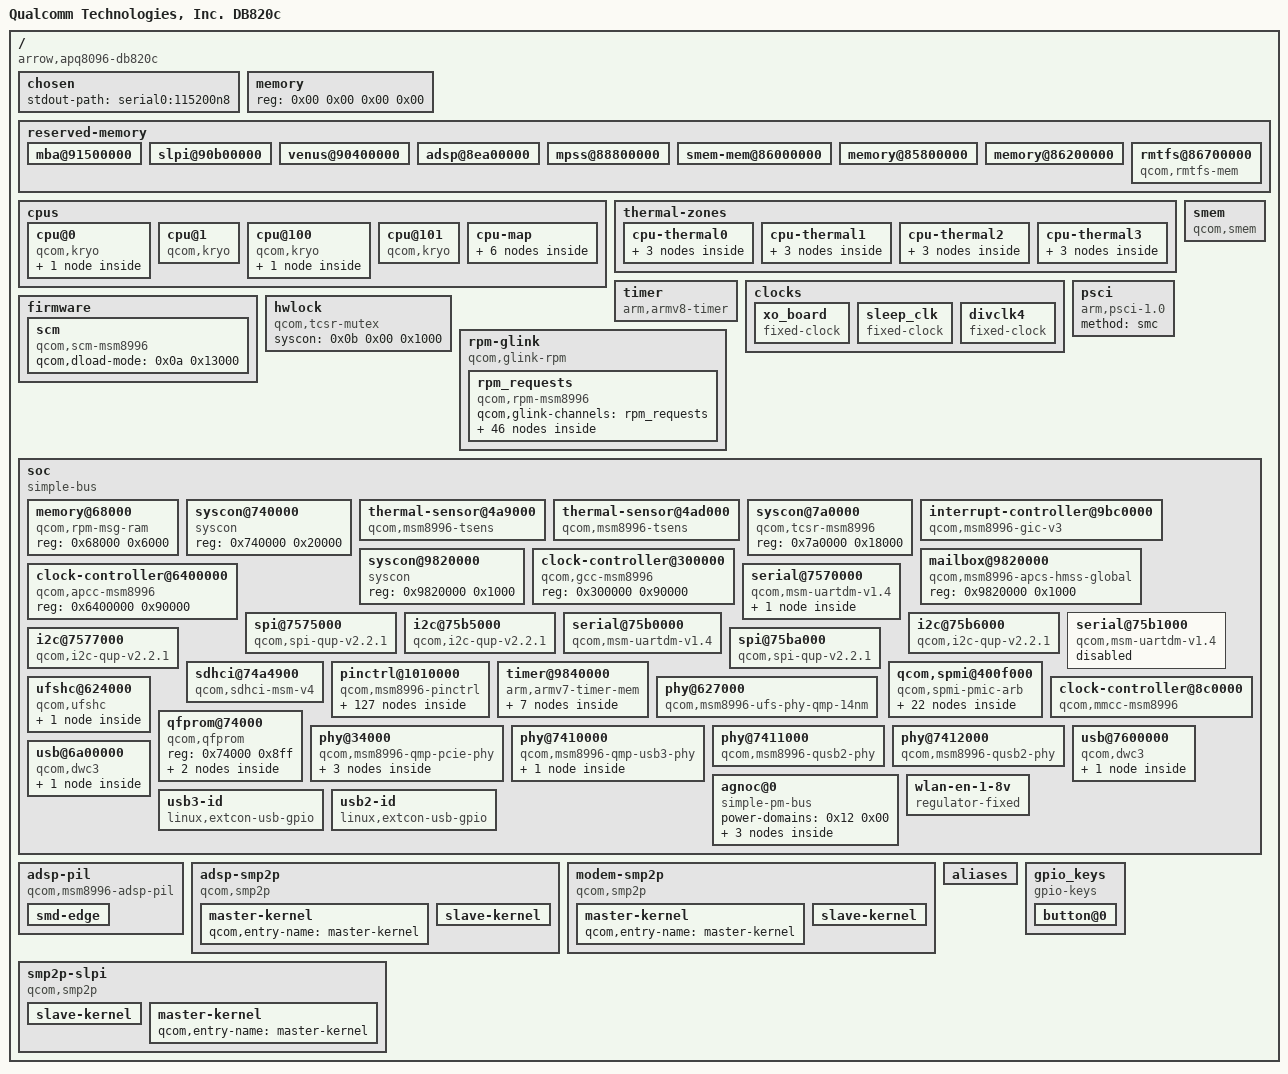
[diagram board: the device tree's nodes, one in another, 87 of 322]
/dts-v1/;

/ {
	model = "Qualcomm Technologies, Inc. DB820c";
	interrupt-parent = <0x01>;
	#address-cells = <0x02>;
	#size-cells = <0x02>;
	compatible = "arrow,apq8096-db820c\0qcom,apq8096-sbc";

	chosen {
		stdout-path = "serial0:115200n8";
	};

	memory {
		device_type = "memory";
		reg = <0x00 0x00 0x00 0x00>;
	};

	reserved-memory {
		#address-cells = <0x02>;
		#size-cells = <0x02>;
		ranges;

		mba@91500000 {
			reg = <0x00 0x91500000 0x00 0x200000>;
			no-map;
		};

		slpi@90b00000 {
			reg = <0x00 0x90b00000 0x00 0xa00000>;
			no-map;
		};

		venus@90400000 {
			reg = <0x00 0x90400000 0x00 0x700000>;
			no-map;
		};

		adsp@8ea00000 {
			reg = <0x00 0x8ea00000 0x00 0x1a00000>;
			no-map;
			phandle = <0x5b>;
		};

		mpss@88800000 {
			reg = <0x00 0x88800000 0x00 0x6200000>;
			no-map;
		};

		smem-mem@86000000 {
			reg = <0x00 0x86000000 0x00 0x200000>;
			no-map;
			phandle = <0x0c>;
		};

		memory@85800000 {
			reg = <0x00 0x85800000 0x00 0x800000>;
			no-map;
		};

		memory@86200000 {
			reg = <0x00 0x86200000 0x00 0x2600000>;
			no-map;
		};

		rmtfs@86700000 {
			compatible = "qcom,rmtfs-mem";
			size = <0x00 0x200000>;
			alloc-ranges = <0x00 0xa0000000 0x00 0x2000000>;
			no-map;
			qcom,client-id = <0x01>;
			qcom,vmid = <0x0f>;
		};
	};

	cpus {
		#address-cells = <0x02>;
		#size-cells = <0x00>;

		cpu@0 {
			device_type = "cpu";
			compatible = "qcom,kryo";
			reg = <0x00 0x00>;
			enable-method = "psci";
			next-level-cache = <0x02>;
			phandle = <0x04>;

			l2-cache {
				compatible = "cache";
				cache-level = <0x02>;
				phandle = <0x02>;
			};
		};

		cpu@1 {
			device_type = "cpu";
			compatible = "qcom,kryo";
			reg = <0x00 0x01>;
			enable-method = "psci";
			next-level-cache = <0x02>;
			phandle = <0x05>;
		};

		cpu@100 {
			device_type = "cpu";
			compatible = "qcom,kryo";
			reg = <0x00 0x100>;
			enable-method = "psci";
			next-level-cache = <0x03>;
			phandle = <0x06>;

			l2-cache {
				compatible = "cache";
				cache-level = <0x02>;
				phandle = <0x03>;
			};
		};

		cpu@101 {
			device_type = "cpu";
			compatible = "qcom,kryo";
			reg = <0x00 0x101>;
			enable-method = "psci";
			next-level-cache = <0x03>;
			phandle = <0x07>;
		};

		cpu-map {

			cluster0 {

				core0 {
					cpu = <0x04>;
				};

				core1 {
					cpu = <0x05>;
				};
			};

			cluster1 {

				core0 {
					cpu = <0x06>;
				};

				core1 {
					cpu = <0x07>;
				};
			};
		};
	};

	thermal-zones {

		cpu-thermal0 {
			polling-delay-passive = <0xfa>;
			polling-delay = <0x3e8>;
			thermal-sensors = <0x08 0x03>;

			trips {

				trip0 {
					temperature = <0x124f8>;
					hysteresis = <0x7d0>;
					type = "passive";
				};

				trip1 {
					temperature = <0x1adb0>;
					hysteresis = <0x7d0>;
					type = "critical";
				};
			};
		};

		cpu-thermal1 {
			polling-delay-passive = <0xfa>;
			polling-delay = <0x3e8>;
			thermal-sensors = <0x08 0x05>;

			trips {

				trip0 {
					temperature = <0x124f8>;
					hysteresis = <0x7d0>;
					type = "passive";
				};

				trip1 {
					temperature = <0x1adb0>;
					hysteresis = <0x7d0>;
					type = "critical";
				};
			};
		};

		cpu-thermal2 {
			polling-delay-passive = <0xfa>;
			polling-delay = <0x3e8>;
			thermal-sensors = <0x08 0x08>;

			trips {

				trip0 {
					temperature = <0x124f8>;
					hysteresis = <0x7d0>;
					type = "passive";
				};

				trip1 {
					temperature = <0x1adb0>;
					hysteresis = <0x7d0>;
					type = "critical";
				};
			};
		};

		cpu-thermal3 {
			polling-delay-passive = <0xfa>;
			polling-delay = <0x3e8>;
			thermal-sensors = <0x08 0x0a>;

			trips {

				trip0 {
					temperature = <0x124f8>;
					hysteresis = <0x7d0>;
					type = "passive";
				};

				trip1 {
					temperature = <0x1adb0>;
					hysteresis = <0x7d0>;
					type = "critical";
				};
			};
		};
	};

	timer {
		compatible = "arm,armv8-timer";
		interrupts = <0x01 0x0d 0x08 0x01 0x0e 0x08 0x01 0x0b 0x08 0x01 0x0a 0x08>;
	};

	clocks {

		xo_board {
			compatible = "fixed-clock";
			#clock-cells = <0x00>;
			clock-frequency = <0x124f800>;
			clock-output-names = "xo_board";
			phandle = <0x25>;
		};

		sleep_clk {
			compatible = "fixed-clock";
			#clock-cells = <0x00>;
			clock-frequency = <0x7ffc>;
			clock-output-names = "sleep_clk";
		};

		divclk4 {
			compatible = "fixed-clock";
			#clock-cells = <0x00>;
			clock-frequency = <0x8000>;
			clock-output-names = "divclk4";
			pinctrl-names = "default";
			pinctrl-0 = <0x09>;
			phandle = <0x16>;
		};
	};

	psci {
		compatible = "arm,psci-1.0";
		method = "smc";
	};

	firmware {

		scm {
			compatible = "qcom,scm-msm8996";
			qcom,dload-mode = <0x0a 0x13000>;
		};
	};

	hwlock {
		compatible = "qcom,tcsr-mutex";
		syscon = <0x0b 0x00 0x1000>;
		#hwlock-cells = <0x01>;
		phandle = <0x0d>;
	};

	smem {
		compatible = "qcom,smem";
		memory-region = <0x0c>;
		hwlocks = <0x0d 0x03>;
	};

	rpm-glink {
		compatible = "qcom,glink-rpm";
		interrupts = <0x00 0xa8 0x01>;
		qcom,rpm-msg-ram = <0x0e>;
		mboxes = <0x0f 0x00>;

		rpm_requests {
			compatible = "qcom,rpm-msm8996";
			qcom,glink-channels = "rpm_requests";

			qcom,rpmcc {
				compatible = "qcom,rpmcc-msm8996";
				#clock-cells = <0x01>;
				phandle = <0x36>;
			};

			pm8994-regulators {
				compatible = "qcom,rpm-pm8994-regulators";
				vdd_l1-supply = <0x10>;
				vdd_l2_l26_l28-supply = <0x10>;
				vdd_l3_l11-supply = <0x10>;
				vdd_l4_l27_l31-supply = <0x10>;
				vdd_l5_l7-supply = <0x11>;
				vdd_l14_l15-supply = <0x11>;
				vdd_l20_l21-supply = <0x11>;
				vdd_l25-supply = <0x10>;

				s1 {
				};

				s2 {
				};

				s3 {
					regulator-min-microvolt = <0x13d620>;
					regulator-max-microvolt = <0x13d620>;
					phandle = <0x10>;
				};

				s4 {
					regulator-min-microvolt = <0x1b7740>;
					regulator-max-microvolt = <0x1b7740>;
					regulator-always-on;
					phandle = <0x39>;
				};

				s5 {
					regulator-min-microvolt = <0x20ce70>;
					regulator-max-microvolt = <0x20ce70>;
					phandle = <0x11>;
				};

				s6 {
				};

				s7 {
					regulator-min-microvolt = "\0\f5";
					regulator-max-microvolt = "\0\f5";
				};

				s8 {
				};

				s9 {
				};

				s10 {
				};

				s11 {
				};

				s12 {
				};

				l1 {
					regulator-min-microvolt = <0xf4240>;
					regulator-max-microvolt = <0xf4240>;
				};

				l2 {
					regulator-min-microvolt = <0x1312d0>;
					regulator-max-microvolt = <0x1312d0>;
				};

				l3 {
					regulator-min-microvolt = <0xcf850>;
					regulator-max-microvolt = <0xcf850>;
				};

				l4 {
					regulator-min-microvolt = <0x12b128>;
					regulator-max-microvolt = <0x12b128>;
				};

				l5 {
				};

				l6 {
					regulator-min-microvolt = <0x124f80>;
					regulator-max-microvolt = <0x124f80>;
				};

				l7 {
				};

				l8 {
					regulator-min-microvolt = <0x1b7740>;
					regulator-max-microvolt = <0x1b7740>;
				};

				l9 {
					regulator-min-microvolt = <0x1b7740>;
					regulator-max-microvolt = <0x1b7740>;
				};

				l10 {
					regulator-min-microvolt = <0x1b7740>;
					regulator-max-microvolt = <0x1b7740>;
				};

				l11 {
					regulator-min-microvolt = <0x118c30>;
					regulator-max-microvolt = <0x118c30>;
				};

				l12 {
					regulator-min-microvolt = <0x1b7740>;
					regulator-max-microvolt = <0x1b7740>;
					phandle = <0x34>;
				};

				l13 {
					regulator-min-microvolt = <0x1b7740>;
					regulator-max-microvolt = <0x2d0370>;
					phandle = <0x30>;
				};

				l14 {
					regulator-min-microvolt = <0x1b7740>;
					regulator-max-microvolt = <0x1b7740>;
				};

				l15 {
					regulator-min-microvolt = <0x1b7740>;
					regulator-max-microvolt = <0x1b7740>;
				};

				l16 {
					regulator-min-microvolt = <0x2932e0>;
					regulator-max-microvolt = <0x2932e0>;
				};

				l17 {
					regulator-min-microvolt = <0x2625a0>;
					regulator-max-microvolt = <0x2625a0>;
				};

				l18 {
					regulator-min-microvolt = <0x2932e0>;
					regulator-max-microvolt = <0x2c4020>;
				};

				l19 {
					regulator-min-microvolt = <0x2dc6c0>;
					regulator-max-microvolt = <0x2dc6c0>;
				};

				l20 {
					regulator-min-microvolt = <0x2d0370>;
					regulator-max-microvolt = <0x2d0370>;
					regulator-allow-set-load;
					phandle = <0x38>;
				};

				l21 {
					regulator-min-microvolt = <0x2d0370>;
					regulator-max-microvolt = <0x2d0370>;
					regulator-allow-set-load;
					regulator-system-load = <0x30d40>;
					phandle = <0x2f>;
				};

				l22 {
					regulator-min-microvolt = <0x325aa0>;
					regulator-max-microvolt = <0x325aa0>;
				};

				l23 {
					regulator-min-microvolt = <0x2ab980>;
					regulator-max-microvolt = <0x2ab980>;
				};

				l24 {
					regulator-min-microvolt = <0x2eebb8>;
					regulator-max-microvolt = <0x2eebb8>;
					phandle = <0x3b>;
				};

				l25 {
					regulator-min-microvolt = <0x124f80>;
					regulator-max-microvolt = <0x124f80>;
					regulator-allow-set-load;
					phandle = <0x35>;
				};

				l26 {
				};

				l27 {
					regulator-min-microvolt = <0xf4240>;
					regulator-max-microvolt = <0xf4240>;
				};

				l28 {
					regulator-min-microvolt = <0xe1d48>;
					regulator-max-microvolt = <0xe1d48>;
					regulator-allow-set-load;
					phandle = <0x33>;
				};

				l29 {
					regulator-min-microvolt = <0x2ab980>;
					regulator-max-microvolt = <0x2ab980>;
				};

				l30 {
					regulator-min-microvolt = <0x1b7740>;
					regulator-max-microvolt = <0x1b7740>;
				};

				l31 {
				};

				l32 {
					regulator-min-microvolt = <0x1b7740>;
					regulator-max-microvolt = <0x1b7740>;
				};
			};
		};
	};

	soc {
		#address-cells = <0x01>;
		#size-cells = <0x01>;
		ranges = <0x00 0x00 0x00 0xffffffff>;
		compatible = "simple-bus";

		memory@68000 {
			compatible = "qcom,rpm-msg-ram";
			reg = <0x68000 0x6000>;
			phandle = <0x0e>;
		};

		syscon@740000 {
			compatible = "syscon";
			reg = <0x740000 0x20000>;
			phandle = <0x0b>;
		};

		thermal-sensor@4a9000 {
			compatible = "qcom,msm8996-tsens";
			reg = <0x4a9000 0x1000 0x4a8000 0x1000>;
			#qcom,sensors = <0x0d>;
			#thermal-sensor-cells = <0x01>;
			phandle = <0x08>;
		};

		thermal-sensor@4ad000 {
			compatible = "qcom,msm8996-tsens";
			reg = <0x4ad000 0x1000 0x4ac000 0x1000>;
			#qcom,sensors = <0x08>;
			#thermal-sensor-cells = <0x01>;
		};

		syscon@7a0000 {
			compatible = "qcom,tcsr-msm8996\0syscon";
			reg = <0x7a0000 0x18000>;
			phandle = <0x0a>;
		};

		interrupt-controller@9bc0000 {
			compatible = "qcom,msm8996-gic-v3\0arm,gic-v3";
			#interrupt-cells = <0x03>;
			interrupt-controller;
			#redistributor-regions = <0x01>;
			redistributor-stride = <0x00 0x40000>;
			reg = <0x9bc0000 0x10000 0x9c00000 0x100000>;
			interrupts = <0x01 0x09 0x04>;
			phandle = <0x01>;
		};

		syscon@9820000 {
			compatible = "syscon";
			reg = <0x9820000 0x1000>;
			phandle = <0x5d>;
		};

		mailbox@9820000 {
			compatible = "qcom,msm8996-apcs-hmss-global";
			reg = <0x9820000 0x1000>;
			#mbox-cells = <0x01>;
			phandle = <0x0f>;
		};

		clock-controller@300000 {
			compatible = "qcom,gcc-msm8996";
			#clock-cells = <0x01>;
			#reset-cells = <0x01>;
			#power-domain-cells = <0x01>;
			reg = <0x300000 0x90000>;
			phandle = <0x12>;
		};

		clock-controller@6400000 {
			compatible = "qcom,apcc-msm8996";
			reg = <0x6400000 0x90000>;
			#clock-cells = <0x01>;
		};

		serial@7570000 {
			compatible = "qcom,msm-uartdm-v1.4\0qcom,msm-uartdm";
			reg = <0x7570000 0x1000>;
			interrupts = <0x00 0x6c 0x04>;
			clocks = <0x12 0x74 0x12 0x6d>;
			clock-names = "core\0iface";
			status = "okay";
			label = "BT-UART";
			pinctrl-names = "default\0sleep";
			pinctrl-0 = <0x13>;
			pinctrl-1 = <0x14>;

			bluetooth {
				compatible = "qcom,qca6174-bt";
				enable-gpios = <0x15 0x13 0x00>;
				clocks = <0x16>;
			};
		};

		spi@7575000 {
			compatible = "qcom,spi-qup-v2.2.1";
			reg = <0x7575000 0x600>;
			interrupts = <0x00 0x5f 0x04>;
			clocks = <0x12 0x6f 0x12 0x6d>;
			clock-names = "core\0iface";
			pinctrl-names = "default\0sleep";
			pinctrl-0 = <0x17>;
			pinctrl-1 = <0x18>;
			#address-cells = <0x01>;
			#size-cells = <0x00>;
			status = "okay";
			label = "LS-SPI0";
		};

		i2c@75b5000 {
			compatible = "qcom,i2c-qup-v2.2.1";
			reg = <0x75b5000 0x1000>;
			interrupts = <0x00 0x65 0x04>;
			clocks = <0x12 0x81 0x12 0x84>;
			clock-names = "iface\0core";
			pinctrl-names = "default\0sleep";
			pinctrl-0 = <0x19>;
			pinctrl-1 = <0x1a>;
			#address-cells = <0x01>;
			#size-cells = <0x00>;
			status = "okay";
			label = "HS-I2C2";
		};

		serial@75b0000 {
			compatible = "qcom,msm-uartdm-v1.4\0qcom,msm-uartdm";
			reg = <0x75b0000 0x1000>;
			interrupts = <0x00 0x72 0x04>;
			clocks = <0x12 0x88 0x12 0x81>;
			clock-names = "core\0iface";
			status = "okay";
			label = "LS-UART1";
			pinctrl-names = "default\0sleep";
			pinctrl-0 = <0x1b>;
			pinctrl-1 = <0x1c>;
		};

		i2c@75b6000 {
			compatible = "qcom,i2c-qup-v2.2.1";
			reg = <0x75b6000 0x1000>;
			interrupts = <0x00 0x66 0x04>;
			clocks = <0x12 0x81 0x12 0x87>;
			clock-names = "iface\0core";
			pinctrl-names = "default\0sleep";
			pinctrl-0 = <0x1d>;
			pinctrl-1 = <0x1e>;
			#address-cells = <0x01>;
			#size-cells = <0x00>;
			status = "okay";
			label = "LS-I2C1";
		};

		serial@75b1000 {
			compatible = "qcom,msm-uartdm-v1.4\0qcom,msm-uartdm";
			reg = <0x75b1000 0x1000>;
			interrupts = <0x00 0x73 0x04>;
			clocks = <0x12 0x8b 0x12 0x81>;
			clock-names = "core\0iface";
			status = "disabled";
			label = "LS-UART0";
			pinctrl-names = "default\0sleep";
			pinctrl-0 = <0x1f>;
			pinctrl-1 = <0x20>;
		};

		i2c@7577000 {
			compatible = "qcom,i2c-qup-v2.2.1";
			reg = <0x7577000 0x1000>;
			interrupts = <0x00 0x61 0x04>;
			clocks = <0x12 0x6d 0x12 0x76>;
			clock-names = "iface\0core";
			pinctrl-names = "default\0sleep";
			pinctrl-0 = <0x21>;
			pinctrl-1 = <0x22>;
			#address-cells = <0x01>;
			#size-cells = <0x00>;
			status = "okay";
			label = "LS-I2C0";
		};

		spi@75ba000 {
			compatible = "qcom,spi-qup-v2.2.1";
			reg = <0x75ba000 0x600>;
			interrupts = <0x00 0x6a 0x04>;
			clocks = <0x12 0x92 0x12 0x81>;
			clock-names = "core\0iface";
			pinctrl-names = "default\0sleep";
			pinctrl-0 = <0x23>;
			pinctrl-1 = <0x24>;
			#address-cells = <0x01>;
			#size-cells = <0x00>;
			status = "okay";
			label = "HS-SPI1";
		};

		sdhci@74a4900 {
			status = "okay";
			compatible = "qcom,sdhci-msm-v4";
			reg = <0x74a4900 0x314 0x74a4000 0x800>;
			reg-names = "hc_mem\0core_mem";
			interrupts = <0x00 0x7d 0x04 0x00 0xdd 0x04>;
			interrupt-names = "hc_irq\0pwr_irq";
			clock-names = "iface\0core\0xo";
			clocks = <0x12 0x68 0x12 0x67 0x25>;
			bus-width = <0x04>;
			pinctrl-names = "default\0sleep";
			pinctrl-0 = <0x26 0x27 0x28 0x29>;
			pinctrl-1 = <0x2a 0x2b 0x2c 0x2d>;
			cd-gpios = <0x2e 0x26 0x01>;
			vmmc-supply = <0x2f>;
			vqmmc-supply = <0x30>;
		};

		pinctrl@1010000 {
			compatible = "qcom,msm8996-pinctrl";
			reg = <0x1010000 0x300000>;
			interrupts = <0x00 0xd0 0x04>;
			gpio-controller;
			#gpio-cells = <0x02>;
			interrupt-controller;
			#interrupt-cells = <0x02>;
			gpio-line-names = "[SPI0_DOUT]\0[SPI0_DIN]\0[SPI0_CS]\0[SPI0_SCLK]\0[UART1_TxD]\0[UART1_RxD]\0[I2C1_SDA]\0[I2C1_SCL]\0GPIO-H\0TP93\0GPIO-G\0[MDP_VSYNC_S]\0NC\0[CSI0_MCLK]\0[CAM_MCLK1]\0[CSI1_MCLK]\0TP99\0[I2C2_SDA]\0[I2C2_SCL]\0[CCI_I2C_SDA1]\0[CCI_I2C_SCL1]\0FLASH_STROBE_EN\0FLASH_STROBE_TRIG\0GPIO-K\0GPIO-D\0GPIO-I\0GPIO-J\0BLSP6_I2C_SDA\0BLSP6_I2C_SCL\0GPIO-B\0GPIO30\0HDMI_CEC\0HDMI_DDC_CLOCK\0HDMI_DDC_DATA\0HDMI_HOT_PLUG_DETECT\0PCIE0_RST_N\0PCIE0_CLKREQ_N\0PCIE0_WAKE\0SD_CARD_DET_N\0TSIF1_SYNC\0W_DISABLE_N\0[BLSP9_UART_TX]\0[BLSP9_UART_RX]\0[BLSP2_UART_CTS_N]\0[BLSP2_UART_RFR_N]\0[BLSP3_UART_TX]\0[BLSP3_UART_RX]\0[I2C0_SDA]\0[I2C0_SCL]\0[UART0_TxD]\0[UART0_RxD]\0[UART0_CTS]\0[UART0_RTS]\0[CODEC_INT1_N]\0[CODEC_INT2_N]\0[BLSP7_I2C_SDA]\0[BLSP7_I2C_SCL]\0MI2S_MCLK\0[PCM_CLK]\0[PCM_FS]\0[PCM_DO]\0[PCM_DI]\0GPIO-E\0TP87\0[CODEC_RST_N]\0[PCM1_CLK]\0[PCM1_SYNC]\0[PCM1_DIN]\0[PCM1_DOUT]\0AUDIO_REF_CLK\0SLIMBUS_CLK\0SLIMBUS_DATA0\0SLIMBUS_DATA1\0NC\0NC\0NC\0NC\0TP94\0NC\0TP95\0GPIO-A\0TP88\0TP89\0TP90\0TP91\0[SD_DAT0]\0[SD_CMD]\0[SD_DAT3]\0[SD_SCLK]\0TSIF1_CLK\0TSIF1_EN\0TSIF1_DATA\0NC\0TSIF2_CLK\0TSIF2_EN\0TSIF2_DATA\0TSIF2_SYNC\0NC\0CAM1_STANDBY_N\0NC\0NC\0[LCD1_RESET_N]\0BOOT_CONFIG1\0USB_HUB_RESET\0CAM1_RST_N\0NC\0NC\0NC\0NC\0NC\0NC\0NC\0NC\0PMI8994_BUA\0PCIE2_RST_N\0PCIE2_CLKREQ_N\0PCIE2_WAKE\0SSC_IRQ_0\0SSC_IRQ_1\0SSC_IRQ_2\0NC\0GPIO121\0NC\0SSC_IRQ_6\0SSC_IRQ_7\0GPIO-C\0BOOT_CONFIG5\0NC\0NC\0BOOT_CONFIG7\0PCIE1_RST_N\0PCIE1_CLKREQ_N\0PCIE1_WAKE\0GPIO-L\0NC\0NC\0BOOT_CONFIG8\0NC\0NC\0GPS_SSBI2\0GPS_SSBI1\0NC\0NC\0NC\0BOOT_CONFIG6\0NC\0NC\0NC\0NC\0NC";
			phandle = <0x2e>;

			blsp1_spi0_default {
				phandle = <0x17>;

				pinmux {
					function = "blsp_spi1";
					pins = "gpio0\0gpio1\0gpio3";
				};

				pinmux_cs {
					function = "gpio";
					pins = "gpio2";
				};

				pinconf {
					pins = "gpio0\0gpio1\0gpio3";
					drive-strength = <0x0c>;
					bias-disable;
				};

				pinconf_cs {
					pins = "gpio2";
					drive-strength = <0x10>;
					bias-disable;
					output-high;
				};
			};

			blsp1_spi0_sleep {
				phandle = <0x18>;

				pinmux {
					function = "gpio";
					pins = "gpio0\0gpio1\0gpio2\0gpio3";
				};

				pinconf {
					pins = "gpio0\0gpio1\0gpio2\0gpio3";
					drive-strength = <0x02>;
					bias-pull-down;
				};
			};

			blsp1_i2c2_default {
				phandle = <0x21>;

				pinmux {
					function = "blsp_i2c3";
					pins = "gpio47\0gpio48";
				};

				pinconf {
					pins = "gpio47\0gpio48";
					drive-strength = <0x10>;
					bias-disable = <0x00>;
				};
			};

			blsp1_i2c2_sleep {
				phandle = <0x22>;

				pinmux {
					function = "gpio";
					pins = "gpio47\0gpio48";
				};

				pinconf {
					pins = "gpio47\0gpio48";
					drive-strength = <0x02>;
					bias-disable = <0x00>;
				};
			};

			blsp2_i2c0 {
				phandle = <0x19>;

				pinmux {
					function = "blsp_i2c7";
					pins = "gpio55\0gpio56";
				};

				pinconf {
					pins = "gpio55\0gpio56";
					drive-strength = <0x10>;
					bias-disable;
				};
			};

			blsp2_i2c0_sleep {
				phandle = <0x1a>;

				pinmux {
					function = "gpio";
					pins = "gpio55\0gpio56";
				};

				pinconf {
					pins = "gpio55\0gpio56";
					drive-strength = <0x02>;
					bias-disable;
				};
			};

			blsp2_uart1_2pins {
				phandle = <0x1b>;

				pinmux {
					function = "blsp_uart8";
					pins = "gpio4\0gpio5";
				};

				pinconf {
					pins = "gpio4\0gpio5";
					drive-strength = <0x10>;
					bias-disable;
				};
			};

			blsp2_uart1_2pins_sleep {
				phandle = <0x1c>;

				pinmux {
					function = "gpio";
					pins = "gpio4\0gpio5";
				};

				pinconf {
					pins = "gpio4\0gpio5";
					drive-strength = <0x02>;
					bias-disable;
				};
			};

			blsp2_uart1_4pins {

				pinmux {
					function = "blsp_uart8";
					pins = "gpio4\0gpio5\0gpio6\0gpio7";
				};

				pinconf {
					pins = "gpio4\0gpio5\0gpio6\0gpio7";
					drive-strength = <0x10>;
					bias-disable;
				};
			};

			blsp2_uart1_4pins_sleep {

				pinmux {
					function = "gpio";
					pins = "gpio4\0gpio5\0gpio6\0gpio7";
				};

				pinconf {
					pins = "gpio4\0gpiio5\0gpio6\0gpio7";
					drive-strength = <0x02>;
					bias-disable;
				};
			};

			blsp2_i2c1 {
				phandle = <0x1d>;

				pinmux {
					function = "blsp_i2c8";
					pins = "gpio6\0gpio7";
				};

				pinconf {
					pins = "gpio6\0gpio7";
					drive-strength = <0x10>;
					bias-disable;
				};
			};

			blsp2_i2c1_sleep {
				phandle = <0x1e>;

				pinmux {
					function = "gpio";
					pins = "gpio6\0gpio7";
				};

				pinconf {
					pins = "gpio6\0gpio7";
					drive-strength = <0x02>;
					bias-disable;
				};
			};

			blsp2_uart2_2pins {

				pinmux {
					function = "blsp_uart9";
					pins = "gpio49\0gpio50";
				};

				pinconf {
					pins = "gpio49\0gpio50";
					drive-strength = <0x10>;
					bias-disable;
				};
			};

			blsp2_uart2_2pins_sleep {

				pinmux {
					function = "gpio";
					pins = "gpio49\0gpio50";
				};

				pinconf {
					pins = "gpio49\0gpio50";
					drive-strength = <0x02>;
					bias-disable;
				};
			};

			blsp2_uart2_4pins {
				phandle = <0x1f>;

				pinmux {
					function = "blsp_uart9";
					pins = "gpio49\0gpio50\0gpio51\0gpio52";
				};

				pinconf {
					pins = "gpio49\0gpio50\0gpio51\0gpio52";
					drive-strength = <0x10>;
					bias-disable;
				};
			};

			blsp2_uart2_4pins_sleep {
				phandle = <0x20>;

				pinmux {
					function = "gpio";
					pins = "gpio49\0gpio50\0gpio51\0gpio52";
				};

				pinconf {
					pins = "gpio49\0gpio50\0gpio51\0gpio52";
					drive-strength = <0x02>;
					bias-disable;
				};
			};

			blsp2_spi5_default {
				phandle = <0x23>;

				pinmux {
					function = "blsp_spi12";
					pins = "gpio85\0gpio86\0gpio88";
				};

				pinmux_cs {
					function = "gpio";
					pins = "gpio87";
				};

				pinconf {
					pins = "gpio85\0gpio86\0gpio88";
					drive-strength = <0x0c>;
					bias-disable;
				};

				pinconf_cs {
					pins = "gpio87";
					drive-strength = <0x10>;
					bias-disable;
					output-high;
				};
			};

			blsp2_spi5_sleep {
				phandle = <0x24>;

				pinmux {
					function = "gpio";
					pins = "gpio85\0gpio86\0gpio87\0gpio88";
				};

				pinconf {
					pins = "gpio85\0gpio86\0gpio87\0gpio88";
					drive-strength = <0x02>;
					bias-pull-down;
				};
			};

			sdc2_clk_on {
				phandle = <0x26>;

				config {
					pins = "sdc2_clk";
					bias-disable;
					drive-strength = <0x10>;
				};
			};

			sdc2_clk_off {
				phandle = <0x2a>;

				config {
					pins = "sdc2_clk";
					bias-disable;
					drive-strength = <0x02>;
				};
			};

			sdc2_cmd_on {
				phandle = <0x27>;

				config {
					pins = "sdc2_cmd";
					bias-pull-up;
					drive-strength = <0x0a>;
				};
			};

			sdc2_cmd_off {
				phandle = <0x2b>;

				config {
					pins = "sdc2_cmd";
					bias-pull-up;
					drive-strength = <0x02>;
				};
			};

			sdc2_data_on {
				phandle = <0x28>;

				config {
					pins = "sdc2_data";
					bias-pull-up;
					drive-strength = <0x0a>;
				};
			};

			sdc2_data_off {
				phandle = <0x2c>;

				config {
					pins = "sdc2_data";
					bias-pull-up;
					drive-strength = <0x02>;
				};
			};

			pcie0_clkreq_default {
				phandle = <0x44>;

				mux {
					pins = "gpio36";
					function = "pci_e0";
				};

				config {
					pins = "gpio36";
					drive-strength = <0x02>;
					bias-pull-up;
				};
			};

			pcie0_perst_default {
				phandle = <0x45>;

				mux {
					pins = "gpio35";
					function = "gpio";
				};

				config {
					pins = "gpio35";
					drive-strength = <0x02>;
					bias-pull-down;
				};
			};

			pcie0_wake_default {
				phandle = <0x46>;

				mux {
					pins = "gpio37";
					function = "gpio";
				};

				config {
					pins = "gpio37";
					drive-strength = <0x02>;
					bias-pull-up;
				};
			};

			pcie0_clkreq_sleep {
				phandle = <0x47>;

				mux {
					pins = "gpio36";
					function = "gpio";
				};

				config {
					pins = "gpio36";
					drive-strength = <0x02>;
					bias-disable;
				};
			};

			pcie0_wake_sleep {
				phandle = <0x48>;

				mux {
					pins = "gpio37";
					function = "gpio";
				};

				config {
					pins = "gpio37";
					drive-strength = <0x02>;
					bias-disable;
				};
			};

			pcie1_clkreq_default {
				phandle = <0x4b>;

				mux {
					pins = "gpio131";
					function = "pci_e1";
				};

				config {
					pins = "gpio131";
					drive-strength = <0x02>;
					bias-pull-up;
				};
			};

			pcie1_perst_default {
				phandle = <0x4c>;

				mux {
					pins = "gpio130";
					function = "gpio";
				};

				config {
					pins = "gpio130";
					drive-strength = <0x02>;
					bias-pull-down;
				};
			};

			pcie1_wake_default {
				phandle = <0x4d>;

				mux {
					pins = "gpio132";
					function = "gpio";
				};

				config {
					pins = "gpio132";
					drive-strength = <0x02>;
					bias-pull-down;
				};
			};

			pcie1_clkreq_sleep {
				phandle = <0x4e>;

				mux {
					pins = "gpio131";
					function = "gpio";
				};

				config {
					pins = "gpio131";
					drive-strength = <0x02>;
					bias-disable;
				};
			};

			pcie1_wake_sleep {
				phandle = <0x4f>;

				mux {
					pins = "gpio132";
					function = "gpio";
				};

				config {
					pins = "gpio132";
					drive-strength = <0x02>;
					bias-disable;
				};
			};

			pcie2_clkreq_default {
				phandle = <0x51>;

				mux {
					pins = "gpio115";
					function = "pci_e2";
				};

				config {
					pins = "gpio115";
					drive-strength = <0x02>;
					bias-pull-up;
				};
			};

			pcie2_perst_default {
				phandle = <0x52>;

				mux {
					pins = "gpio114";
					function = "gpio";
				};

				config {
					pins = "gpio114";
					drive-strength = <0x02>;
					bias-pull-down;
				};
			};

			pcie2_wake_default {
				phandle = <0x53>;

				mux {
					pins = "gpio116";
					function = "gpio";
				};

				config {
					pins = "gpio116";
					drive-strength = <0x02>;
					bias-pull-down;
				};
			};

			pcie2_clkreq_sleep {
				phandle = <0x54>;

				mux {
					pins = "gpio115";
					function = "gpio";
				};

				config {
					pins = "gpio115";
					drive-strength = <0x02>;
					bias-disable;
				};
			};

			pcie2_wake_sleep {
				phandle = <0x55>;

				mux {
					pins = "gpio116";
					function = "gpio";
				};

				config {
					pins = "gpio116";
					drive-strength = <0x02>;
					bias-disable;
				};
			};

			sdc2_cd_on {
				phandle = <0x29>;

				mux {
					pins = "gpio38";
					function = "gpio";
				};

				config {
					pins = "gpio38";
					bias-pull-up;
					drive-strength = <0x10>;
				};
			};

			sdc2_cd_off {
				phandle = <0x2d>;

				mux {
					pins = "gpio38";
					function = "gpio";
				};

				config {
					pins = "gpio38";
					bias-pull-up;
					drive-strength = <0x02>;
				};
			};

			blsp1_uart1_default {
				phandle = <0x13>;

				mux {
					pins = "gpio41\0gpio42\0gpio43\0gpio44";
					function = "blsp_uart2";
				};

				config {
					pins = "gpio41\0gpio42\0gpio43\0gpio44";
					drive-strength = <0x10>;
					bias-disable;
				};
			};

			blsp1_uart1_sleep {
				phandle = <0x14>;

				mux {
					pins = "gpio41\0gpio42\0gpio43\0gpio44";
					function = "gpio";
				};

				config {
					pins = "gpio41\0gpio42\0gpio43\0gpio44";
					drive-strength = <0x02>;
					bias-disable;
				};
			};
		};

		timer@9840000 {
			#address-cells = <0x01>;
			#size-cells = <0x01>;
			ranges;
			compatible = "arm,armv7-timer-mem";
			reg = <0x9840000 0x1000>;
			clock-frequency = <0x124f800>;

			frame@9850000 {
				frame-number = <0x00>;
				interrupts = <0x00 0x1f 0x04 0x00 0x1e 0x04>;
				reg = <0x9850000 0x1000 0x9860000 0x1000>;
			};

			frame@9870000 {
				frame-number = <0x01>;
				interrupts = <0x00 0x20 0x04>;
				reg = <0x9870000 0x1000>;
				status = "disabled";
			};

			frame@9880000 {
				frame-number = <0x02>;
				interrupts = <0x00 0x21 0x04>;
				reg = <0x9880000 0x1000>;
				status = "disabled";
			};

			frame@9890000 {
				frame-number = <0x03>;
				interrupts = <0x00 0x22 0x04>;
				reg = <0x9890000 0x1000>;
				status = "disabled";
			};

			frame@98a0000 {
				frame-number = <0x04>;
				interrupts = <0x00 0x23 0x04>;
				reg = <0x98a0000 0x1000>;
				status = "disabled";
			};

			frame@98b0000 {
				frame-number = <0x05>;
				interrupts = <0x00 0x24 0x04>;
				reg = <0x98b0000 0x1000>;
				status = "disabled";
			};

			frame@98c0000 {
				frame-number = <0x06>;
				interrupts = <0x00 0x25 0x04>;
				reg = <0x98c0000 0x1000>;
				status = "disabled";
			};
		};

		qcom,spmi@400f000 {
			compatible = "qcom,spmi-pmic-arb";
			reg = <0x400f000 0x1000 0x4400000 0x800000 0x4c00000 0x800000 0x5800000 0x200000 0x400a000 0x2100>;
			reg-names = "core\0chnls\0obsrvr\0intr\0cnfg";
			interrupt-names = "periph_irq";
			interrupts = <0x00 0x146 0x04>;
			qcom,ee = <0x00>;
			qcom,channel = <0x00>;
			#address-cells = <0x02>;
			#size-cells = <0x00>;
			interrupt-controller;
			#interrupt-cells = <0x04>;

			pmic@0 {
				compatible = "qcom,pm8994\0qcom,spmi-pmic";
				reg = <0x00 0x00>;
				#address-cells = <0x01>;
				#size-cells = <0x00>;

				rtc@6000 {
					compatible = "qcom,pm8941-rtc";
					reg = <0x6000 0x6100>;
					reg-names = "rtc\0alarm";
					interrupts = <0x00 0x61 0x01 0x01>;
				};

				gpios@c000 {
					compatible = "qcom,pm8994-gpio";
					reg = <0xc000>;
					gpio-controller;
					#gpio-cells = <0x02>;
					interrupts = <0x00 0xc0 0x00 0x00 0x00 0xc1 0x00 0x00 0x00 0xc2 0x00 0x00 0x00 0xc3 0x00 0x00 0x00 0xc4 0x00 0x00 0x00 0xc5 0x00 0x00 0x00 0xc6 0x00 0x00 0x00 0xc7 0x00 0x00 0x00 0xc8 0x00 0x00 0x00 0xc9 0x00 0x00 0x00 0xca 0x00 0x00 0x00 0xcb 0x00 0x00 0x00 0xcc 0x00 0x00 0x00 0xcd 0x00 0x00 0x00 0xce 0x00 0x00 0x00 0xcf 0x00 0x00 0x00 0xd0 0x00 0x00 0x00 0xd1 0x00 0x00 0x00 0xd2 0x00 0x00 0x00 0xd3 0x00 0x00 0x00 0xd4 0x00 0x00 0x00 0xd5 0x00 0x00>;
					pinctrl-names = "default";
					pinctrl-0 = <0x31 0x32>;
					gpio-line-names = "NC\0KEY_VOLP_N\0NC\0BL1_PWM\0GPIO-F\0BL1_EN\0NC\0WLAN_EN\0NC\0NC\0NC\0NC\0NC\0NC\0DIVCLK1\0DIVCLK2\0DIVCLK3\0DIVCLK4\0BT_EN\0PMIC_SLB\0PMIC_BUA\0USB_VBUS_DET";
					phandle = <0x15>;

					pm8994_gpio5 {
						phandle = <0x31>;

						pinconf {
							pins = "gpio5";
							output-low;
							power-source = <0x02>;
						};
					};

					bt_en_gpios {
						phandle = <0x32>;

						pinconf {
							pins = "gpio19";
							function = "normal";
							output-low;
							power-source = <0x02>;
							qcom,drive-strength = <0x01>;
							bias-pull-down;
						};
					};

					wlan_en_gpios {
						phandle = <0x59>;

						pinconf {
							pins = "gpio8";
							function = "normal";
							output-low;
							power-source = <0x02>;
							qcom,drive-strength = <0x01>;
							bias-pull-down;
						};
					};

					pm8996_gpio2 {
						phandle = <0x5e>;

						pinconf {
							pins = "gpio2";
							function = "normal";
							input-enable;
							drive-push-pull;
							bias-pull-up;
							qcom,drive-strength = <0x00>;
							power-source = <0x02>;
						};
					};

					divclk4 {
						phandle = <0x09>;

						pinconf {
							pins = "gpio18";
							function = "func2";
							bias-disable;
							power-source = <0x02>;
						};
					};

					pm8996_gpio22 {
						phandle = <0x56>;

						pinconf {
							pins = "gpio22";
							function = "normal";
							input-enable;
							bias-pull-down;
							qcom,drive-strength = <0x00>;
							power-source = <0x02>;
						};
					};
				};

				mpps@a000 {
					compatible = "qcom,pm8994-mpp";
					reg = <0xa000>;
					gpio-controller;
					#gpio-cells = <0x02>;
					interrupts = <0x00 0xa0 0x00 0x00 0x00 0xa1 0x00 0x00 0x00 0xa2 0x00 0x00 0x00 0xa3 0x00 0x00 0x00 0xa4 0x00 0x00 0x00 0xa5 0x00 0x00 0x00 0xa6 0x00 0x00 0x00 0xa7 0x00 0x00>;
					gpio-line-names = "VDDPX_BIAS\0WIFI_LED\0NC\0BT_LED\0PM_MPP05\0PM_MPP06\0PM_MPP07\0NC";
				};
			};

			pmic@1 {
				compatible = "qcom,pm8994\0qcom,spmi-pmic";
				reg = <0x01 0x00>;
				#address-cells = <0x01>;
				#size-cells = <0x00>;
			};

			pmic@2 {
				compatible = "qcom,pmi8994\0qcom,spmi-pmic";
				reg = <0x02 0x00>;
				#address-cells = <0x01>;
				#size-cells = <0x00>;

				gpios@c000 {
					compatible = "qcom,pmi8994-gpio\0qcom,spmi-gpio";
					reg = <0xc000>;
					gpio-controller;
					#gpio-cells = <0x02>;
					interrupts = <0x02 0xc0 0x00 0x00 0x02 0xc1 0x00 0x00 0x02 0xc2 0x00 0x00 0x02 0xc3 0x00 0x00 0x02 0xc4 0x00 0x00 0x02 0xc5 0x00 0x00 0x02 0xc6 0x00 0x00 0x02 0xc7 0x00 0x00 0x02 0xc8 0x00 0x00 0x02 0xc9 0x00 0x00>;
					gpio-line-names = "NC\0SPKR_AMP_EN1\0SPKR_AMP_EN2\0TP61\0NC\0USB2_VBUS_DET\0NC\0NC\0NC\0NC";
					phandle = <0x57>;

					pmi8996_gpio6 {
						phandle = <0x58>;

						pinconf {
							pins = "gpio6";
							function = "normal";
							input-enable;
							bias-pull-down;
							qcom,drive-strength = <0x00>;
							power-source = <0x02>;
						};
					};
				};
			};

			pmic@3 {
				compatible = "qcom,pmi8994\0qcom,spmi-pmic";
				reg = <0x03 0x00>;
				#address-cells = <0x01>;
				#size-cells = <0x00>;
			};
		};

		phy@627000 {
			compatible = "qcom,msm8996-ufs-phy-qmp-14nm";
			reg = <0x627000 0xda8>;
			reg-names = "phy_mem";
			#phy-cells = <0x00>;
			vdda-phy-supply = <0x33>;
			vdda-pll-supply = <0x34>;
			vdda-phy-max-microamp = <0x47cc>;
			vdda-pll-max-microamp = <0x24e0>;
			vddp-ref-clk-supply = <0x35>;
			vddp-ref-clk-max-microamp = <0x64>;
			vddp-ref-clk-always-on;
			clock-names = "ref_clk_src\0ref_clk";
			clocks = <0x36 0x54 0x12 0xd7>;
			status = "okay";
			phandle = <0x37>;
		};

		ufshc@624000 {
			compatible = "qcom,ufshc";
			reg = <0x624000 0x2500>;
			interrupts = <0x00 0x109 0x04>;
			phys = <0x37>;
			phy-names = "ufsphy";
			vcc-supply = <0x38>;
			vccq-supply = <0x35>;
			vccq2-supply = <0x39>;
			vcc-max-microamp = <0x927c0>;
			vccq-max-microamp = <0x6ddd0>;
			vccq2-max-microamp = <0x6ddd0>;
			power-domains = <0x12 0x08>;
			clock-names = "core_clk_src\0core_clk\0bus_clk\0bus_aggr_clk\0iface_clk\0core_clk_unipro_src\0core_clk_unipro\0core_clk_ice\0ref_clk\0tx_lane0_sync_clk\0rx_lane0_sync_clk";
			clocks = <0x12 0x49 0x12 0xc1 0x12 0x52 0x12 0xd1 0x12 0xc2 0x12 0x4a 0x12 0xc8 0x12 0xc9 0x36 0x54 0x12 0xc5 0x12 0xc6>;
			freq-table-hz = <0x5f5e100 0xbebc200 0x00 0x00 0x00 0x00 0x00 0x00 0x00 0x00 0x8f0d180 0x11e1a300 0x00 0x00 0x00 0x00 0x00 0x00 0x00 0x00 0x00 0x00>;
			lanes-per-direction = <0x01>;
			status = "okay";

			ufs_variant {
				compatible = "qcom,ufs_variant";
			};
		};

		clock-controller@8c0000 {
			compatible = "qcom,mmcc-msm8996";
			#clock-cells = <0x01>;
			#reset-cells = <0x01>;
			#power-domain-cells = <0x01>;
			reg = <0x8c0000 0x40000>;
			assigned-clocks = <0x3a 0x0f 0x3a 0x03 0x3a 0x07 0x3a 0x09 0x3a 0x0b>;
			assigned-clock-rates = <0x25317c00 0x30479e80 0x3a699d00 0x39387000 0x312c8040>;
			phandle = <0x3a>;
		};

		qfprom@74000 {
			compatible = "qcom,qfprom";
			reg = <0x74000 0x8ff>;
			#address-cells = <0x01>;
			#size-cells = <0x01>;

			hstx_trim@24e {
				reg = <0x24e 0x02>;
				bits = <0x05 0x04>;
				phandle = <0x3c>;
			};

			hstx_trim@24f {
				reg = <0x24f 0x01>;
				bits = <0x01 0x04>;
				phandle = <0x3d>;
			};
		};

		phy@34000 {
			compatible = "qcom,msm8996-qmp-pcie-phy";
			reg = <0x34000 0x488>;
			#clock-cells = <0x01>;
			#address-cells = <0x01>;
			#size-cells = <0x01>;
			ranges;
			clocks = <0x12 0xc0 0x12 0xbf 0x12 0xd8>;
			clock-names = "aux\0cfg_ahb\0ref";
			vdda-phy-supply = <0x33>;
			vdda-pll-supply = <0x34>;
			resets = <0x12 0x55 0x12 0x65 0x12 0x66>;
			reset-names = "phy\0common\0cfg";
			status = "okay";

			lane@35000 {
				reg = <0x35000 0x130 0x35200 0x200 0x35400 0x1dc>;
				#phy-cells = <0x00>;
				clock-output-names = "pcie_0_pipe_clk_src";
				clocks = <0x12 0xb4>;
				clock-names = "pipe0";
				resets = <0x12 0x50>;
				reset-names = "lane0";
				phandle = <0x43>;
			};

			lane@36000 {
				reg = <0x36000 0x130 0x36200 0x200 0x36400 0x1dc>;
				#phy-cells = <0x00>;
				clock-output-names = "pcie_1_pipe_clk_src";
				clocks = <0x12 0xb9>;
				clock-names = "pipe1";
				resets = <0x12 0x52>;
				reset-names = "lane1";
				phandle = <0x4a>;
			};

			lane@37000 {
				reg = <0x37000 0x130 0x37200 0x200 0x37400 0x1dc>;
				#phy-cells = <0x00>;
				clock-output-names = "pcie_2_pipe_clk_src";
				clocks = <0x12 0xbe>;
				clock-names = "pipe2";
				resets = <0x12 0x54>;
				reset-names = "lane2";
				phandle = <0x50>;
			};
		};

		phy@7410000 {
			compatible = "qcom,msm8996-qmp-usb3-phy";
			reg = <0x7410000 0x1c4>;
			#clock-cells = <0x01>;
			#address-cells = <0x01>;
			#size-cells = <0x01>;
			ranges;
			clocks = <0x12 0x5e 0x12 0x63 0x12 0xd5>;
			clock-names = "aux\0cfg_ahb\0ref";
			vdda-phy-supply = <0x33>;
			vdda-pll-supply = <0x34>;
			resets = <0x12 0x67 0x12 0x68>;
			reset-names = "phy\0common";
			status = "okay";

			lane@7410200 {
				reg = <0x7410200 0x200 0x7410400 0x130 0x7410600 0x1a8>;
				#phy-cells = <0x00>;
				clock-output-names = "usb3_phy_pipe_clk_src";
				clocks = <0x12 0x5f>;
				clock-names = "pipe0";
				phandle = <0x41>;
			};
		};

		phy@7411000 {
			compatible = "qcom,msm8996-qusb2-phy";
			reg = <0x7411000 0x180>;
			#phy-cells = <0x00>;
			clocks = <0x12 0x63 0x12 0xda>;
			clock-names = "cfg_ahb\0ref";
			vdda-pll-supply = <0x34>;
			vdda-phy-dpdm-supply = <0x3b>;
			resets = <0x12 0x09>;
			nvmem-cells = <0x3c>;
			status = "okay";
			phandle = <0x40>;
		};

		phy@7412000 {
			compatible = "qcom,msm8996-qusb2-phy";
			reg = <0x7412000 0x180>;
			#phy-cells = <0x00>;
			clocks = <0x12 0x63 0x12 0xd9>;
			clock-names = "cfg_ahb\0ref";
			vdda-pll-supply = <0x34>;
			vdda-phy-dpdm-supply = <0x3b>;
			resets = <0x12 0x0a>;
			nvmem-cells = <0x3d>;
			status = "okay";
			phandle = <0x3e>;
		};

		usb@7600000 {
			compatible = "qcom,dwc3";
			#address-cells = <0x01>;
			#size-cells = <0x01>;
			ranges;
			clocks = <0x12 0x55 0x12 0x60 0x12 0x62 0x12 0x61 0x12 0x63>;
			assigned-clocks = <0x12 0x62 0x12 0x60>;
			assigned-clock-rates = <0x124f800 0x3938700>;
			power-domains = <0x12 0x04>;
			status = "okay";

			dwc3@7600000 {
				compatible = "snps,dwc3";
				reg = <0x7600000 0xcc00>;
				interrupts = <0x00 0x8a 0x04>;
				phys = <0x3e>;
				phy-names = "usb2-phy";
				snps,dis_u2_susphy_quirk;
				snps,dis_enblslpm_quirk;
				extcon = <0x3f>;
				dr_mode = "otg";
				maximum-speed = "high-speed";
			};
		};

		usb@6a00000 {
			compatible = "qcom,dwc3";
			#address-cells = <0x01>;
			#size-cells = <0x01>;
			ranges;
			clocks = <0x12 0x51 0x12 0x5b 0x12 0xd2 0x12 0x5d 0x12 0x5c 0x12 0x63>;
			assigned-clocks = <0x12 0x5d 0x12 0x5b>;
			assigned-clock-rates = <0x124f800 0x7270e00>;
			power-domains = <0x12 0x04>;
			status = "okay";

			dwc3@6a00000 {
				compatible = "snps,dwc3";
				reg = <0x6a00000 0xcc00>;
				interrupts = <0x00 0x83 0x04>;
				phys = <0x40 0x41>;
				phy-names = "usb2-phy\0usb3-phy";
				snps,dis_u2_susphy_quirk;
				snps,dis_enblslpm_quirk;
				extcon = <0x42>;
				dr_mode = "otg";
			};
		};

		agnoc@0 {
			power-domains = <0x12 0x00>;
			compatible = "simple-pm-bus";
			#address-cells = <0x01>;
			#size-cells = <0x01>;
			ranges;

			pcie@600000 {
				compatible = "qcom,pcie-msm8996\0snps,dw-pcie";
				status = "okay";
				power-domains = <0x12 0x05>;
				bus-range = <0x00 0xff>;
				num-lanes = <0x01>;
				reg = <0x600000 0x2000 0xc000000 0xf1d 0xc000f20 0xa8 0xc100000 0x100000>;
				reg-names = "parf\0dbi\0elbi\0config";
				phys = <0x43>;
				phy-names = "pciephy";
				#address-cells = <0x03>;
				#size-cells = <0x02>;
				ranges = <0x1000000 0x00 0xc200000 0xc200000 0x00 0x100000 0x2000000 0x00 0xc300000 0xc300000 0x00 0xd00000>;
				interrupts = <0x00 0x195 0x04>;
				interrupt-names = "msi";
				#interrupt-cells = <0x01>;
				interrupt-map-mask = <0x00 0x00 0x00 0x07>;
				interrupt-map = <0x00 0x00 0x00 0x01 0x01 0x00 0xf4 0x04 0x00 0x00 0x00 0x02 0x01 0x00 0xf5 0x04 0x00 0x00 0x00 0x03 0x01 0x00 0xf7 0x04 0x00 0x00 0x00 0x04 0x01 0x00 0xf8 0x04>;
				pinctrl-names = "default\0sleep";
				pinctrl-0 = <0x44 0x45 0x46>;
				pinctrl-1 = <0x47 0x45 0x48>;
				vdda-supply = <0x33>;
				linux,pci-domain = <0x00>;
				clocks = <0x12 0xb4 0x12 0xb3 0x12 0xb2 0x12 0xb1 0x12 0xb0>;
				clock-names = "pipe\0aux\0cfg\0bus_master\0bus_slave";
				perst-gpio = <0x2e 0x23 0x01>;
				vddpe-3v3-supply = <0x49>;
			};

			pcie@608000 {
				compatible = "qcom,pcie-msm8996\0snps,dw-pcie";
				power-domains = <0x12 0x06>;
				bus-range = <0x00 0xff>;
				num-lanes = <0x01>;
				status = "okay";
				reg = <0x608000 0x2000 0xd000000 0xf1d 0xd000f20 0xa8 0xd100000 0x100000>;
				reg-names = "parf\0dbi\0elbi\0config";
				phys = <0x4a>;
				phy-names = "pciephy";
				#address-cells = <0x03>;
				#size-cells = <0x02>;
				ranges = <0x1000000 0x00 0xd200000 0xd200000 0x00 0x100000 0x2000000 0x00 0xd300000 0xd300000 0x00 0xd00000>;
				interrupts = <0x00 0x19d 0x04>;
				interrupt-names = "msi";
				#interrupt-cells = <0x01>;
				interrupt-map-mask = <0x00 0x00 0x00 0x07>;
				interrupt-map = <0x00 0x00 0x00 0x01 0x01 0x00 0x110 0x04 0x00 0x00 0x00 0x02 0x01 0x00 0x111 0x04 0x00 0x00 0x00 0x03 0x01 0x00 0x112 0x04 0x00 0x00 0x00 0x04 0x01 0x00 0x113 0x04>;
				pinctrl-names = "default\0sleep";
				pinctrl-0 = <0x4b 0x4c 0x4d>;
				pinctrl-1 = <0x4e 0x4c 0x4f>;
				vdda-supply = <0x33>;
				linux,pci-domain = <0x01>;
				clocks = <0x12 0xb9 0x12 0xb8 0x12 0xb7 0x12 0xb6 0x12 0xb5>;
				clock-names = "pipe\0aux\0cfg\0bus_master\0bus_slave";
				perst-gpio = <0x2e 0x82 0x01>;
			};

			pcie@610000 {
				compatible = "qcom,pcie-msm8996\0snps,dw-pcie";
				power-domains = <0x12 0x07>;
				bus-range = <0x00 0xff>;
				num-lanes = <0x01>;
				status = "okay";
				reg = <0x610000 0x2000 0xe000000 0xf1d 0xe000f20 0xa8 0xe100000 0x100000>;
				reg-names = "parf\0dbi\0elbi\0config";
				phys = <0x50>;
				phy-names = "pciephy";
				#address-cells = <0x03>;
				#size-cells = <0x02>;
				ranges = <0x1000000 0x00 0xe200000 0xe200000 0x00 0x100000 0x2000000 0x00 0xe300000 0xe300000 0x00 0x1d00000>;
				device_type = "pci";
				interrupts = <0x00 0x1a5 0x04>;
				interrupt-names = "msi";
				#interrupt-cells = <0x01>;
				interrupt-map-mask = <0x00 0x00 0x00 0x07>;
				interrupt-map = <0x00 0x00 0x00 0x01 0x01 0x00 0x8e 0x04 0x00 0x00 0x00 0x02 0x01 0x00 0x8f 0x04 0x00 0x00 0x00 0x03 0x01 0x00 0x90 0x04 0x00 0x00 0x00 0x04 0x01 0x00 0x91 0x04>;
				pinctrl-names = "default\0sleep";
				pinctrl-0 = <0x51 0x52 0x53>;
				pinctrl-1 = <0x54 0x52 0x55>;
				vdda-supply = <0x33>;
				linux,pci-domain = <0x02>;
				clocks = <0x12 0xbe 0x12 0xbd 0x12 0xbc 0x12 0xbb 0x12 0xba>;
				clock-names = "pipe\0aux\0cfg\0bus_master\0bus_slave";
				perst-gpio = <0x2e 0x72 0x01>;
			};
		};

		usb3-id {
			compatible = "linux,extcon-usb-gpio";
			id-gpio = <0x15 0x16 0x00>;
			pinctrl-names = "default";
			pinctrl-0 = <0x56>;
			phandle = <0x42>;
		};

		usb2-id {
			compatible = "linux,extcon-usb-gpio";
			id-gpio = <0x57 0x06 0x00>;
			pinctrl-names = "default";
			pinctrl-0 = <0x58>;
			phandle = <0x3f>;
		};

		wlan-en-1-8v {
			pinctrl-names = "default";
			pinctrl-0 = <0x59>;
			compatible = "regulator-fixed";
			regulator-name = "wlan-en-regulator";
			regulator-min-microvolt = <0x1b7740>;
			regulator-max-microvolt = <0x1b7740>;
			gpio = <0x15 0x08 0x00>;
			startup-delay-us = <0x11170>;
			enable-active-high;
			phandle = <0x49>;
		};
	};

	adsp-pil {
		compatible = "qcom,msm8996-adsp-pil";
		interrupts-extended = <0x01 0x00 0xa2 0x01 0x5a 0x00 0x01 0x5a 0x01 0x01 0x5a 0x02 0x01 0x5a 0x03 0x01>;
		interrupt-names = "wdog\0fatal\0ready\0handover\0stop-ack";
		clocks = <0x25>;
		clock-names = "xo";
		memory-region = <0x5b>;
		qcom,smem-states = <0x5c 0x00>;
		qcom,smem-state-names = "stop";

		smd-edge {
			interrupts = <0x00 0x9c 0x01>;
			label = "lpass";
			qcom,ipc = <0x5d 0x10 0x08>;
			qcom,smd-edge = <0x01>;
			qcom,remote-pid = <0x02>;
		};
	};

	adsp-smp2p {
		compatible = "qcom,smp2p";
		qcom,smem = <0x1bb 0x1ad>;
		interrupts = <0x00 0x9e 0x01>;
		qcom,ipc = <0x5d 0x10 0x0a>;
		qcom,local-pid = <0x00>;
		qcom,remote-pid = <0x02>;

		master-kernel {
			qcom,entry-name = "master-kernel";
			#qcom,smem-state-cells = <0x01>;
			phandle = <0x5c>;
		};

		slave-kernel {
			qcom,entry-name = "slave-kernel";
			interrupt-controller;
			#interrupt-cells = <0x02>;
			phandle = <0x5a>;
		};
	};

	modem-smp2p {
		compatible = "qcom,smp2p";
		qcom,smem = <0x1b3 0x1ac>;
		interrupts = <0x00 0x1c3 0x01>;
		qcom,ipc = <0x5d 0x10 0x0e>;
		qcom,local-pid = <0x00>;
		qcom,remote-pid = <0x01>;

		master-kernel {
			qcom,entry-name = "master-kernel";
			#qcom,smem-state-cells = <0x01>;
		};

		slave-kernel {
			qcom,entry-name = "slave-kernel";
			interrupt-controller;
			#interrupt-cells = <0x02>;
		};
	};

	smp2p-slpi {
		compatible = "qcom,smp2p";
		qcom,smem = <0x1e1 0x1ae>;
		interrupts = <0x00 0xb2 0x01>;
		qcom,ipc = <0x5d 0x10 0x1a>;
		qcom,local-pid = <0x00>;
		qcom,remote-pid = <0x03>;

		slave-kernel {
			qcom,entry-name = "slave-kernel";
			interrupt-controller;
			#interrupt-cells = <0x02>;
		};

		master-kernel {
			qcom,entry-name = "master-kernel";
			#qcom,smem-state-cells = <0x01>;
		};
	};

	aliases {
		serial0 = "/soc/serial@75b0000";
		serial1 = "/soc/serial@75b1000";
		serial2 = "/soc/serial@7570000";
		i2c0 = "/soc/i2c@7577000";
		i2c1 = "/soc/i2c@75b6000";
		i2c2 = "/soc/i2c@75b5000";
		spi0 = "/soc/spi@7575000";
		spi1 = "/soc/spi@75ba000";
	};

	gpio_keys {
		compatible = "gpio-keys";
		#address-cells = <0x01>;
		#size-cells = <0x00>;
		autorepeat;
		pinctrl-names = "default";
		pinctrl-0 = <0x5e>;

		button@0 {
			label = "Volume Up";
			linux,code = <0x73>;
			gpios = <0x15 0x02 0x01>;
		};
	};
};
